# PIC18LF2431 register map
Vendor: Microchip
Architecture 18xxxx. Special function registers and configuration words.
Registers are 8-bit, read-write, reset 0x0 unless marked. A register's access mark holds for its fields unless they carry their own. Addresses are absolute, and some are shared; only a register's first bit layout is shown; lines under a group give offsets from that group; [hi:lo] are bit positions; {n}, {i} and the like mark numbered series; 'fields as' and 'values as' point back to an identical list; <NAME> marks a mode.

## Further device data
pins=1: MCLR/VPP; 2: RA0/AN0; 3: RA1/AN1; 4: RA2/AN2/VREF-/CAP1/INDX; 5: RA3/AN3/VREF+/CAP2/QEA; 6: RA4/AN4/CAP3/QEB; 7: AVDD; 8: AVSS; 9: OSC1/CLKI/RA7; 10: OSC2/CLKO/RA6; 11: RC0/T1OSO/T1CKI; 12: RC1/T1OSI/CCP2/FLTA; 13: RC2/CCP1/FLTB; 14: RC3/T0CKI/T5CKI/INT0; 15: RC4/INT1/SDI/SDA; 16: RC5/INT2/SCK/SCL; 17: RC6/TX/CK/SS; 18: RC7/RX/DT/SDO; 19: VSS; 20: VDD; 21: RB0/PWM0; 22: RB1/PWM1; 23: RB2/PWM2; 24: RB3/PWM3; 25: RB4/KBI0/PWM5; 26: RB5/KBI1/PWM4/PGM; 27: RB6/KBI2/PGC; 28: RB7/KBI3/PGD

## CONFIG — Configuration words, addresses in ProgramSpace
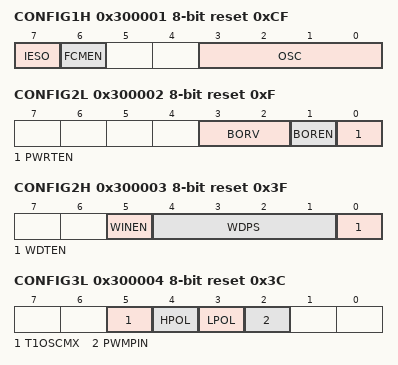
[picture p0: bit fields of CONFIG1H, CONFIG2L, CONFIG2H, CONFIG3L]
0x300001 CONFIG1H reset 0xCF
  [7] IESO — Internal External Oscillator Switchover bit
    1=ON (Internal External Switchover mode enabled); 0=OFF (Internal External Switchover mode disabled)
  [6] FCMEN — Fail-Safe Clock Monitor Enable bit
    1=ON (Fail-Safe Clock Monitor enabled); 0=OFF (Fail-Safe Clock Monitor disabled)
  [3:0] OSC — Oscillator Selection bits
    0b11xx=RC (11XX External RC oscillator, CLKO function on RA6); 0b101x=RC1 (101X External RC oscillator, CLKO function on RA6); 9=IRC (Internal oscillator block, CLKO function on RA6 and port function on RA7); 8=IRCIO (Internal oscillator block, port function on RA6 and port function on RA7); 7=RCIO (External RC oscillator, port function on RA6); 6=HSPLL (HS oscillator, PLL enabled (clock frequency = 4 x FOSC1)); 5=ECIO (EC oscillator, port function on RA6); 4=EC (EC oscillator, CLKO function on RA6); 3=RC2 (External RC oscillator, CLKO function on RA6); 2=HS (HS oscillator); 1=XT (XT oscillator); 0=LP (LP oscillator)
0x300002 CONFIG2L reset 0xF
  [3:2] BORV — Brown Out Reset Voltage bits
    2=VBOR set to 2.7V; 1=VBOR set to 4.2V; 0=VBOR set to 4.5V
  [1] BOREN — Brown-out Reset Enable bits
    1=ON (Brown-out Reset enabled); 0=OFF (Brown-out Reset disabled)
  [0] PWRTEN — Power-up Timer Enable bit
    1=OFF (PWRT disabled); 0=ON (PWRT enabled)
0x300003 CONFIG2H reset 0x3F
  [5] WINEN — Watchdog Timer Window Enable bit
    1=OFF (WDT window disabled); 0=ON (WDT window enabledbled)
  [4:1] WDPS — Watchdog Timer Postscale Select bits
    15=1:32768; 14=1:16384; 13=1:8192; 12=1:4096; 11=1:2048; 10=1:1024; 9=1:512; 8=1:256; 7=1:128; 6=1:64; 5=1:32; 4=1:16; 3=1:8; 2=1:4; 1=1:2; 0=1:1
  [0] WDTEN — Watchdog Timer Enable bit
    1=ON (WDT enabled); 0=OFF (WDT disabled (control is placed on the SWDTEN bit))
0x300004 CONFIG3L reset 0x3C
  [5] T1OSCMX — Timer1 Oscillator MUX
    1=ON (Low-power Timer1 operation when microcontroller is in Sleep mode); 0=OFF (Standard (legacy) Timer1 oscillator operation)
  [4] HPOL — High-Side Transistors Polarity
    1=HIGH (PWM1, 3, 5 and 7 are active-high); 0=LOW (PWM1, 3, 5 and 7 are active-low)
  [3] LPOL — Low-Side Transistors Polarity
    1=HIGH (PWM0, 2, 4 and 6 are active-high); 0=LOW (PWM0, 2, 4 and 6 are active-low)
  [2] PWMPIN — PWM output pins Reset state control
    1=OFF (PWM outputs disabled upon Reset (default)); 0=ON (PWM outputs drive active states upon Reset)
0x300005 CONFIG3H reset 0x9D
  [7] MCLRE — MCLR Pin Enable bit
    1=ON (Enabled); 0=OFF (Disabled)
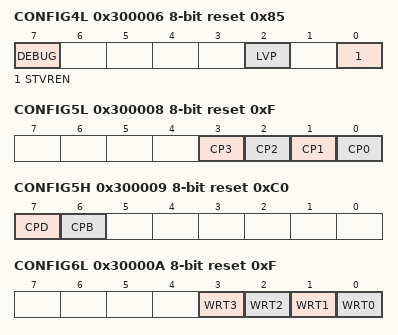
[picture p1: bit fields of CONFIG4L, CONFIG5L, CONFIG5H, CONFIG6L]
0x300006 CONFIG4L reset 0x85
  [7] DEBUG — Background Debugger Enable bit
    1=OFF (Background debugger disabled; RB6 and RB7 configured as general purpose I/O pins); 0=ON (Background debugger enabled; RB6 and RB7 are dedicated to In-Circuit Debug)
  [2] LVP — Low-Voltage ICSP Enable bit
    1=ON (Low-voltage ICSP enabled); 0=OFF (Low-voltage ICSP disabled)
  [0] STVREN — Stack Full/Underflow Reset Enable bit
    1=ON (Stack full/underflow will cause Reset); 0=OFF (Stack full/underflow will not cause Reset)
0x300008 CONFIG5L reset 0xF
  [3] CP3 — Code Protection bit
    1=OFF (Block 3 (003000-003FFFh) not code-protected); 0=ON (Block 3 (003000-003FFFh) code-protected)
  [2] CP2 — Code Protection bit
    1=OFF (Block 2 (002000-002FFFh) not code-protected); 0=ON (Block 2 (002000-002FFFh) code-protected)
  [1] CP1 — Code Protection bit
    1=OFF (Block 1 (001000-001FFF) not code-protected); 0=ON (Block 1 (001000-001FFF) code-protected)
  [0] CP0 — Code Protection bit
    1=OFF (Block 0 (000200-000FFFh) not code-protected); 0=ON (Block 0 (000200-000FFFh) code-protected)
0x300009 CONFIG5H reset 0xC0
  [7] CPD — Data EEPROM Code Protection bit
    1=OFF (Data EEPROM not code-protected); 0=ON (Data EEPROM code-protected)
  [6] CPB — Boot Block Code Protection bit
    1=OFF (Boot Block (000000-0001FFh) not code-protected); 0=ON (Boot Block (000000-0001FFh) code-protected)
0x30000A CONFIG6L reset 0xF
  [3] WRT3 — Write Protection bit
    1=OFF (Block 3 (003000-003FFFh) not write-protected); 0=ON (Block 3 (003000-003FFFh) write-protected)
  [2] WRT2 — Write Protection bit
    1=OFF (Block 2 (002000-002FFFh) not write-protected); 0=ON (Block 2 (002000-002FFFh) write-protected)
  [1] WRT1 — Write Protection bit
    1=OFF (Block 1 (001000-001FFF) not write-protected); 0=ON (Block 1 (001000-001FFF) write-protected)
  [0] WRT0 — Write Protection bit
    1=OFF (Block 0 (000200-000FFFh) not write-protected); 0=ON (Block 0 (000200-000FFFh) write-protected)
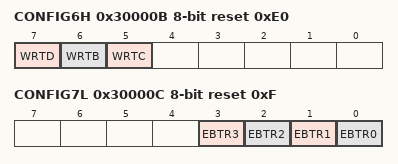
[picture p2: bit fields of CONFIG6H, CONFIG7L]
0x30000B CONFIG6H reset 0xE0
  [7] WRTD — Data EEPROM Write Protection bit
    1=OFF (Data EEPROM not write-protected); 0=ON (Data EEPROM write-protected)
  [6] WRTB — Boot Block Write Protection bit
    1=OFF (Boot Block (000000-0001FFh) not write-protected); 0=ON (Boot Block (000000-0001FFh) write-protected)
  [5] WRTC — Configuration Register Write Protection bit
    1=OFF (Configuration registers (300000-3000FFh) not write-protected); 0=ON (Configuration registers (300000-3000FFh) write-protected)
0x30000C CONFIG7L reset 0xF
  [3] EBTR3 — Table Read Protection bit
    1=OFF (Block 3 (003000-003FFFh) not protected from table reads executed in other blocks); 0=ON (Block 3 (003000-003FFFh) protected from table reads executed in other blocks)
  [2] EBTR2 — Table Read Protection bit
    1=OFF (Block 2 (002000-002FFFh) not protected from table reads executed in other blocks); 0=ON (Block 2 (002000-002FFFh) protected from table reads executed in other blocks)
  [1] EBTR1 — Table Read Protection bit
    1=OFF (Block 1 (001000-001FFF) not protected from table reads executed in other blocks); 0=ON (Block 1 (001000-001FFF) protected from table reads executed in other blocks)
  [0] EBTR0 — Table Read Protection bit
    1=OFF (Block 0 (000200-000FFFh) not protected from table reads executed in other blocks); 0=ON (Block 0 (000200-000FFFh) protected from table reads executed in other blocks)
0x30000D CONFIG7H reset 0x40
  [6] EBTRB — Boot Block Table Read Protection bit
    1=OFF (Boot Block (000000-0001FFh) not protected from table reads executed in other blocks); 0=ON (Boot Block (000000-0001FFh) not protected from table reads executed in other blocks)
